# WKUP_CTRL_MMR0_WKUP_CTRL_MMR0_IP_CTRL_MMRS_43030000h register map
Vendor: Texas Instruments
Peripheral module from a debugger description file (folder am62L).
Registers are 32-bit, read-write, reset 0x0 unless marked. A register's access mark holds for its fields unless they carry their own. Offsets are as the file gives them; lines under a group give offsets from that group; [hi:lo] are bit positions; {n}, {i} and the like mark numbered series; 'fields as' and 'values as' point back to an identical list; <NAME> marks a mode.

## WKUP_CTRL_MMR0_IP_CTRL_MMRS
{0x1000+4i} WKUP_CTRL_MMR0_IP_CTRL_MMRS_DBOUNCE_CFG{i} (i=1..6) — Configures IO debounce selections
  [5:0] DBOUNCE_CFG{i}_DB_CFG — Configures the debounce period used for I/Os with PADCONFIGx_DEBOUNCE_SEL = {i}. Debounce period is specified as a number of CLK0 or CLK1 clock cycles. For all inputs except EQEP inputs, CLK0 is CLK_32K_RC and CLK1 is HFOSC0_CLKOUT. For EQEP, faster clocks are used. CLK0 is HFOSC0_CLKOUT and CLK1 is MAIN_SYSCLK0/2. 0 BYPASS1 DB_64_CLK02 DB_96_CLK03 DB_128_CLK04 DB_160_CLK05 DB_192_CLK06 DB_224_CLK07 DB_256_CLK08 DB_288_CLK09 DB_320_CLK010 DB_352_CLK011 DB_384_CLK012 DB_416_CLK013 DB_448_CLK014 DB_480_CLK016 DB_544_CLK017 DB_576_CLK018 DB_608_CLK019 DB_640_CLK020 DB_672_CLK021 DB_704_CLK022 DB_512_CLK023 DB_1024_CLK024 DB_1536_CLK025 DB_2048_CLK026 DB_2560_CLK027 DB_3072_CLK028 DB_3584_CLK029 DB_4096_CLK030 DB_4608_CLK031 DB_5120_CLK032 DB_1_CLK133 DB_2_CLK134 DB_3_CLK135 DB_4_CLK136 DB_5_CLK137 DB_6_CLK138 DB_7_CLK139 DB_8_CLK140 DB_9_CLK141 DB_10_CLK142 DB_11_CLK143 DB_12_CLK144 DB_13_CLK145 DB_14_CLK146 DB_15_CLK147 DB_16_CLK148 DB_17_CLK149 DB_18_CLK150 DB_19_CLK151 DB_20_CLK152 DB_21_CLK153 DB_22_CLK154 DB_512_CLK155 DB_1024_CLK156 DB_1536_CLK157 DB_2048_CLK158 DB_2560_CLK159 DB_3072_CLK160 DB_3584_CLK161 DB_4096_CLK162 DB_4608_CLK163 DB_5120_CLK1
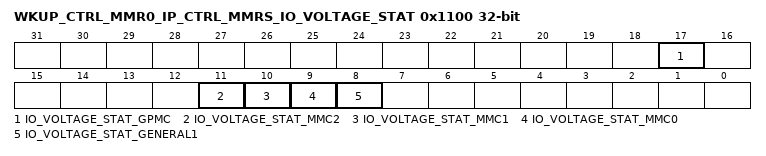
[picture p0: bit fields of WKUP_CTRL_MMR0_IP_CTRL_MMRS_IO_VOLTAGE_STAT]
0x1100 WKUP_CTRL_MMR0_IP_CTRL_MMRS_IO_VOLTAGE_STAT ro — Reads returns the current value detected by the IO voltage mode circuit for each dual rail I/O Group. Only valid when corresponding VDDSHV rails is powered on.
  [17] IO_VOLTAGE_STAT_GPMC — Detected voltage for GPMC I/O group (VDDSHV0) 0 IOGROUP_3P3V1 IOGROUP_1P8V
  [11] IO_VOLTAGE_STAT_MMC2 — Detected voltage for the MMC2 I/O group (VDDSHV4) 0 IOGROUP_3P3V1 IOGROUP_1P8V
  [10] IO_VOLTAGE_STAT_MMC1 — Detected voltage for the MMC1 I/O group (VDDSHV3) 0 IOGROUP_3P3V1 IOGROUP_1P8V
  [9] IO_VOLTAGE_STAT_MMC0 — Detected voltage for the MMC0 I/O group (VDDSHV2) 0 IOGROUP_3P3V1 IOGROUP_1P8V
  [8] IO_VOLTAGE_STAT_GENERAL1 — Detected voltage for the General1 I/O group (VDDSHV1) Reset Source: mod_por_rst_n
{0x1300+4i} WKUP_CTRL_MMR0_IP_CTRL_MMRS_SDIO{i}_CTRL (i=0..2) — Controls drive strength of MMC{i} SDIO mode pins
  [4:0] SDIO{i}_CTRL_DRV_STR — Selects the SDIO drive strength. Default is an efuse trimmed value, trimmed to aproximately 40 Ohms. Expected values for trim are between DS_10 and DS_19. Changing the value of this field is not recommended.Note: Values other than the reset value may invalidate the datasheet timing parameters and therefore should not be used. 1 DS_12 DS_23 DS_34 DS_45 DS_56 DS_67 DS_78 DS_89 DS_910 DS_1011 DS_1112 DS_1213 DS_1314 DS_1415 DS_1516 DS_1617 DS_1718 DS_1819 DS_1920 DS_2021 DS_2122 DS_2223 DS_2324 DS_2425 DS_2526 DS_2627 DS_2728 DS_2829 DS_2930 DS_30
